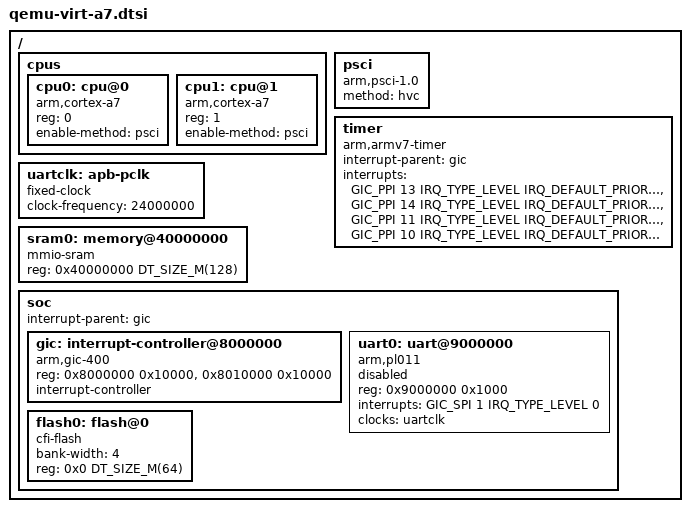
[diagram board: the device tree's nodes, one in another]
/*
 * Copyright (c) Qualcomm Technologies, Inc. and/or its subsidiaries.
 *
 * SPDX-License-Identifier: Apache-2.0
 */

/*
 * Derived from DTS extracted with:
 *
 *   qemu-system-aarch64 -machine virt,gic-version=2,secure=off -cpu cortex-a7
 *         -smp 2 -machine dumpdtb=virt.dtb
 *
 *   dtc -I dtb -O dts virt.dtb
 */

#include <mem.h>
#include <arm/armv7-a.dtsi>
#include <zephyr/dt-bindings/interrupt-controller/arm-gic.h>

/ {
	#address-cells = <1>;
	#size-cells = <1>;

	cpus {
		#address-cells = <1>;
		#size-cells = <0>;

		cpu0: cpu@0 {
			device_type = "cpu";
			compatible = "arm,cortex-a7";
			reg = <0>;
			enable-method = "psci";
		};

		cpu1: cpu@1 {
			device_type = "cpu";
			compatible = "arm,cortex-a7";
			reg = <1>;
			enable-method = "psci";
		};
	};

	psci {
		compatible = "arm,psci-1.0", "arm,psci-0.2", "arm,psci";
		method = "hvc";
	};

	timer {
		compatible = "arm,armv7-timer";
		interrupt-parent = <&gic>;
		interrupts = <GIC_PPI 13 IRQ_TYPE_LEVEL
			      IRQ_DEFAULT_PRIORITY>,
			     <GIC_PPI 14 IRQ_TYPE_LEVEL
			      IRQ_DEFAULT_PRIORITY>,
			     <GIC_PPI 11 IRQ_TYPE_LEVEL
			      IRQ_DEFAULT_PRIORITY>,
			     <GIC_PPI 10 IRQ_TYPE_LEVEL
			      IRQ_DEFAULT_PRIORITY>;
	};

	uartclk: apb-pclk {
		compatible = "fixed-clock";
		clock-frequency = <24000000>;
		#clock-cells = <0>;
	};

	sram0: memory@40000000 {
		compatible = "mmio-sram";
		reg = <0x40000000 DT_SIZE_M(128)>;
	};

	soc {
		interrupt-parent = <&gic>;

		gic: interrupt-controller@8000000 {
			compatible = "arm,gic-400", "arm,gic-v2", "arm,gic";
			reg = <0x8000000 0x10000>,
			      <0x8010000 0x10000>;
			interrupt-controller;
			#interrupt-cells = <4>;
			status = "okay";
		};

		uart0: uart@9000000 {
			compatible = "arm,pl011";
			reg = <0x9000000 0x1000>;
			status = "disabled";
			interrupts = <GIC_SPI 1 IRQ_TYPE_LEVEL 0>;
			interrupt-names = "irq_0";
			clocks = <&uartclk>;
		};

		flash0: flash@0 {
			compatible = "cfi-flash";
			bank-width = <4>;
			reg = <0x0 DT_SIZE_M(64)>;
		};
	};
};
